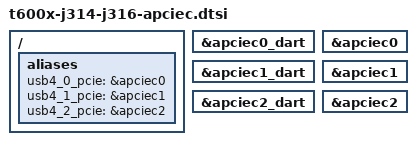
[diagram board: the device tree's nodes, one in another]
// SPDX-License-Identifier: GPL-2.0+ OR MIT
/*
 * Board part for the 14"/16" MacBook Pro (j314s/j314c/j316s/j316c): USB4
 * ports 0-2. Included from the T600x j314/j316 .dts files only:
 * t600x-j314-j316.dtsi is shared with T602x boards, which have no APCIEC
 * nodes.
 */

/ {
	aliases {
		/* used by m1n1 to fill the APCIEC tunables */
		usb4_0_pcie = &apciec0;
		usb4_1_pcie = &apciec1;
		usb4_2_pcie = &apciec2;
	};
};

&apciec0_dart {
	status = "okay";
};

&apciec0 {
	status = "okay";
};

&apciec1_dart {
	status = "okay";
};

&apciec1 {
	status = "okay";
};

&apciec2_dart {
	status = "okay";
};

&apciec2 {
	status = "okay";
};
